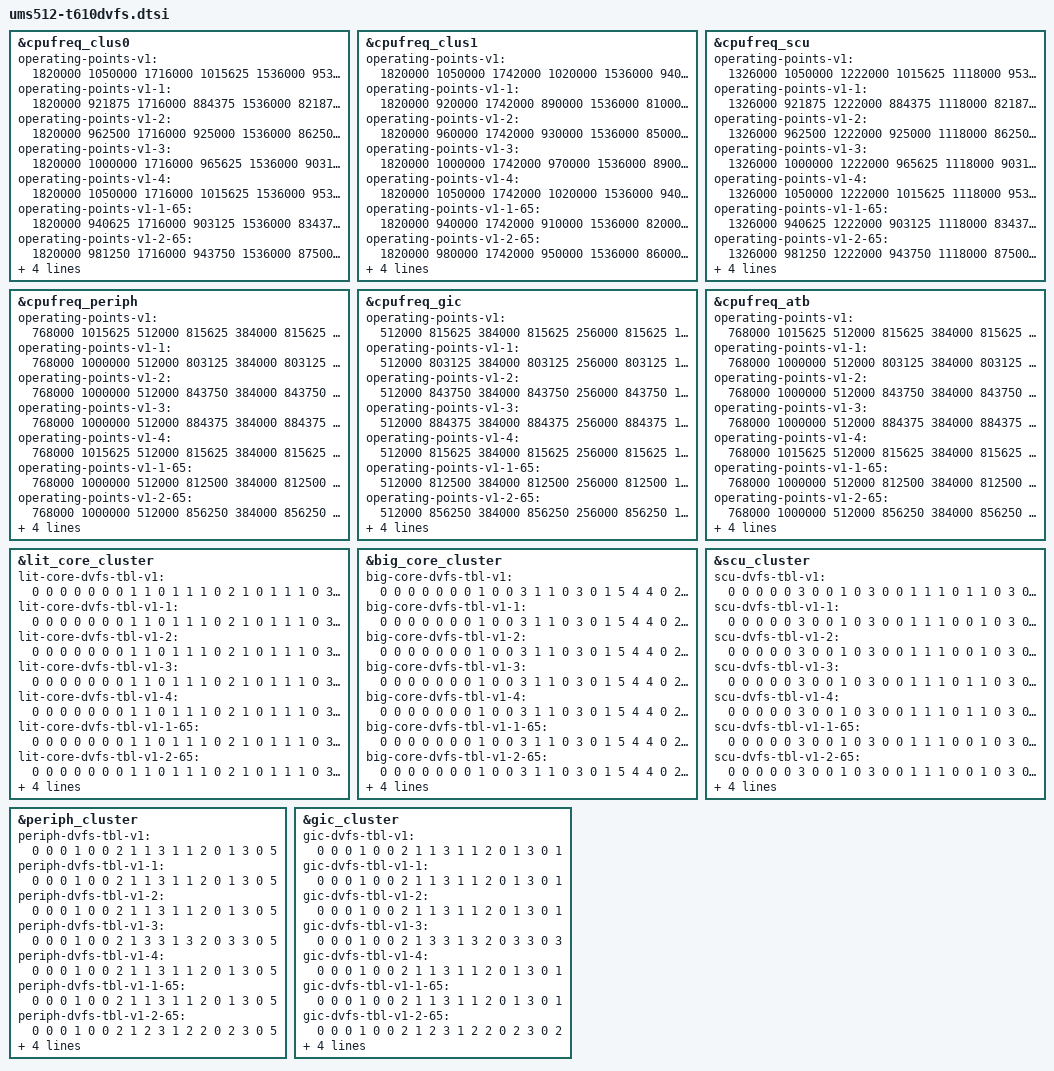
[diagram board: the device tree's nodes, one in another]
// SPDX-License-Identifier: (GPL-2.0+ OR MIT)
/*
 * Unisoc Sharkl5Pro platform T610 SOC DVFS DTS file
 *
 * Copyright (C) 2019, Unisoc Communications Inc.
 */

#include "sharkl5Pro.dtsi"
#include "ums512.dtsi"

&cpufreq_clus0 {
	/* operating-points-v1-0-0
	 * v0/v1-soc_ver 0-binning 0-temp
	 * v0-T618 v1-T610
	 */
	operating-points-v1 = <
		/* kHZ   uV */
		1820000 1050000
		1716000 1015625
		1536000 953125
		1482000 934375
		1228800 846875
		1144000 815625
		962000  753125
		768000  753125
		614400  753125
	>;

	operating-points-v1-1 = <
		/* kHZ   uV */
		1820000 921875
		1716000 884375
		1536000 821875
		1482000 803125
		1228800 750000
		1144000 750000
		962000  750000
		768000  750000
		614400  750000
	>;

	operating-points-v1-2 = <
		/* kHZ   uV */
		1820000 962500
		1716000 925000
		1536000 862500
		1482000 843750
		1228800 756250
		1144000 756250
		962000  756250
		768000  756250
		614400  756250
	>;

	operating-points-v1-3 = <
		/* kHZ   uV */
		1820000 1000000
		1716000 965625
		1536000 903125
		1482000 884375
		1228800 796875
		1144000 765625
		962000  750000
		768000  750000
		614400  750000
	>;

	operating-points-v1-4 = <
		/* kHZ   uV */
		1820000 1050000
		1716000 1015625
		1536000 953125
		1482000 934375
		1228800 846875
		1144000 815625
		962000  753125
		768000  753125
		614400  753125
	>;

	operating-points-v1-1-65 = <
		/* kHZ   uV */
		1820000 940625
		1716000 903125
		1536000 834375
		1482000 812500
		1228800 750000
		1144000 750000
		962000  750000
		768000  750000
		614400  750000
	>;

	operating-points-v1-2-65 = <
		/* kHZ   uV */
		1820000 981250
		1716000 943750
		1536000 875000
		1482000 856250
		1228800 759375
		1144000 750000
		962000  750000
		768000  750000
		614400  750000
	>;

	operating-points-v1-3-65 = <
		/* kHZ   uV */
		1820000 1021875
		1716000 984375
		1536000 915625
		1482000 896875
		1228800 803125
		1144000 771875
		962000  750000
		768000  750000
		614400  750000
	>;

	operating-points-v1-4-65 = <
		/* kHZ   uV */
		1716000 1034375
		1536000 965625
		1482000 946875
		1228800 853125
		1144000 821875
		962000  756250
		768000  756250
		614400  756250
	>;
};

&cpufreq_clus1 {
	operating-points-v1 = <
		/* kHZ   uV */
		1820000  1050000
		1742000  1020000
		1536000	 940000
		1482000	 920000
		1228800	 820000
	>;

	operating-points-v1-1 = <
		/* kHZ   uV */
		1820000  920000
		1742000  890000
		1536000	 810000
		1482000	 790000
		1228800	 750000
	>;

	operating-points-v1-2 = <
		/* kHZ   uV */
		1820000  960000
		1742000  930000
		1536000	 850000
		1482000	 830000
		1228800	 750000
	>;

	operating-points-v1-3 = <
		/* kHZ   uV */
		1820000  1000000
		1742000  970000
		1536000	 890000
		1482000	 870000
		1228800	 770000
	>;

	operating-points-v1-4 = <
		/* kHZ   uV */
		1820000  1050000
		1742000  1020000
		1536000	 940000
		1482000	 920000
		1228800	 820000
	>;

	operating-points-v1-1-65 = <
		/* kHZ   uV */
		1820000  940000
		1742000  910000
		1536000	 820000
		1482000	 800000
		1228800	 750000
	>;

	operating-points-v1-2-65 = <
		/* kHZ   uV */
		1820000  980000
		1742000  950000
		1536000	 860000
		1482000	 840000
		1228800	 750000
	>;

	operating-points-v1-3-65 = <
		/* kHZ   uV */
		1820000  1020000
		1742000  990000
		1536000	 900000
		1482000	 880000
		1228800	 770000
	>;

	operating-points-v1-4-65 = <
		/* kHZ   uV */
		1742000  1040000
		1536000	 960000
		1482000	 930000
		1228800	 830000
	>;
};

&cpufreq_scu {
	operating-points-v1 = <
		/* kHz   uV */
		1326000 1050000
		1222000 1015625
		1118000 953125
		1014000 934375
		962000  846875
		768000  815625
		650000  753125
		546000  753125
	>;

	operating-points-v1-1 = <
		/* kHz   uV */
		1326000 921875
		1222000 884375
		1118000 821875
		1014000 803125
		962000  750000
		768000  750000
		650000  750000
		546000  750000
	>;

	operating-points-v1-2 = <
		/* kHz   uV */
		1326000 962500
		1222000 925000
		1118000 862500
		1014000 843750
		962000  756250
		768000  756250
		650000  756250
		546000  756250
	>;

	operating-points-v1-3 = <
		/* kHz   uV */
		1326000 1000000
		1222000 965625
		1118000 903125
		1014000 884375
		962000  796875
		768000  765625
		650000  750000
		546000  750000
	>;

	operating-points-v1-4 = <
		/* kHz   uV */
		1326000 1050000
		1222000 1015625
		1118000 953125
		1014000 934375
		962000  846875
		768000  815625
		650000  753125
		546000  753125
	>;

	operating-points-v1-1-65 = <
		/* kHz   uV */
		1326000 940625
		1222000 903125
		1118000 834375
		1014000 812500
		962000  750000
		768000  750000
		650000  750000
		546000  750000
	>;

	operating-points-v1-2-65 = <
		/* kHz   uV */
		1326000 981250
		1222000 943750
		1118000 875000
		1014000 856250
		962000  759375
		768000  750000
		650000  750000
		546000  750000
	>;

	operating-points-v1-3-65 = <
		/* kHz   uV */
		1326000 1021875
		1222000 984375
		1118000 915625
		1014000 896875
		962000  803125
		768000  771875
		650000  750000
		546000  750000
	>;

	operating-points-v1-4-65 = <
		/* kHz   uV */
		1222000 1034375
		1118000 965625
		1014000 946875
		962000  853125
		768000  821875
		650000  756250
		546000  756250
	>;
};

&cpufreq_periph {
	operating-points-v1 = <
		/* kHZ  uV */
		768000 1015625
		512000 815625
		384000 815625
		256000 815625
		153600 753125
	>;

	operating-points-v1-1 = <
		/* kHZ  uV */
		768000 1000000
		512000 803125
		384000 803125
		256000 803125
		153600 750000
	>;

	operating-points-v1-2 = <
		/* kHZ  uV */
		768000 1000000
		512000 843750
		384000 843750
		256000 843750
		153600 756250
	>;

	operating-points-v1-3 = <
		/* kHZ  uV */
		768000 1000000
		512000 884375
		384000 884375
		256000 884375
		153600 750000
	>;

	operating-points-v1-4 = <
		/* kHZ  uV */
		768000 1015625
		512000 815625
		384000 815625
		256000 815625
		153600 753125
	>;

	operating-points-v1-1-65 = <
		/* kHZ  uV */
		768000 1000000
		512000 812500
		384000 812500
		256000 812500
		153600 750000
	>;

	operating-points-v1-2-65 = <
		/* kHZ  uV */
		768000 1000000
		512000 856250
		384000 856250
		256000 856250
		153600 750000
	>;

	operating-points-v1-3-65 = <
		/* kHZ  uV */
		768000 1021875
		512000 803125
		384000 803125
		256000 803125
		153600 750000
	>;

	operating-points-v1-4-65 = <
		/* kHZ  uV */
		768000 1034375
		512000 821875
		384000 821875
		256000 821875
		153600 756250
	>;
};

&cpufreq_gic {
	operating-points-v1 = <
		/* kHZ  uV */
		512000 815625
		384000 815625
		256000 815625
		192000 815625
		153600 753125
	>;

	operating-points-v1-1 = <
		/* kHZ  uV */
		512000 803125
		384000 803125
		256000 803125
		192000 803125
		153600 750000
	>;

	operating-points-v1-2 = <
		/* kHZ  uV */
		512000 843750
		384000 843750
		256000 843750
		192000 843750
		153600 756250
	>;

	operating-points-v1-3 = <
		/* kHZ  uV */
		512000 884375
		384000 884375
		256000 884375
		192000 884375
		153600 750000
	>;

	operating-points-v1-4 = <
		/* kHZ  uV */
		512000 815625
		384000 815625
		256000 815625
		192000 815625
		153600 753125
	>;

	operating-points-v1-1-65 = <
		/* kHZ  uV */
		512000 812500
		384000 812500
		256000 812500
		192000 812500
		153600 750000
	>;

	operating-points-v1-2-65 = <
		/* kHZ  uV */
		512000 856250
		384000 856250
		256000 856250
		192000 856250
		153600 750000
	>;

	operating-points-v1-3-65 = <
		/* kHZ  uV */
		512000 803125
		384000 803125
		256000 803125
		192000 803125
		153600 750000
	>;

	operating-points-v1-4-65 = <
		/* kHZ  uV */
		512000 821875
		384000 821875
		256000 821875
		192000 821875
		153600 756250
	>;
};

&cpufreq_atb {
	operating-points-v1 = <
		/* kHZ  uV */
		768000 1015625
		512000 815625
		384000 815625
		256000 753125
		153600 753125
	>;

	operating-points-v1-1 = <
		/* kHZ  uV */
		768000 1000000
		512000 803125
		384000 803125
		256000 750000
		153600 750000
	>;

	operating-points-v1-2 = <
		/* kHZ  uV */
		768000 1000000
		512000 843750
		384000 843750
		256000 756250
		153600 756250
	>;

	operating-points-v1-3 = <
		/* kHZ  uV */
		768000 1000000
		512000 884375
		384000 884375
		256000 750000
		153600 750000
	>;

	operating-points-v1-4 = <
		/* kHZ  uV */
		768000 1015625
		512000 815625
		384000 815625
		256000 753125
		153600 753125
	>;

	operating-points-v1-1-65 = <
		/* kHZ  uV */
		768000 1000000
		512000 812500
		384000 812500
		256000 750000
		153600 750000
	>;

	operating-points-v1-2-65 = <
		/* kHZ  uV */
		768000 1000000
		512000 856250
		384000 856250
		256000 750000
		153600 750000
	>;

	operating-points-v1-3-65 = <
		/* kHZ  uV */
		768000 1021875
		512000 803125
		384000 803125
		256000 750000
		153600 750000
	>;

	operating-points-v1-4-65 = <
		/* kHZ  uV */
		768000 1034375
		512000 821875
		384000 821875
		256000 756250
		153600 756250
	>;
};

&lit_core_cluster{
	/* lit-core-dvfs-tbl-v1-0-0
	 * v0/v1-soc_ver v0-T618 v1-T610 0-binning 0-temp
	 * sel, div, vol, vote_scu, vote_peri, vote_gic, mpllx
	 */
	lit-core-dvfs-tbl-v1 = <
		0 0 0 0 0 0 0
		1 1 0 1 1 1 0
		2 1 0 1 1 1 0
		3 0 0 2 1 1 0
		3 0 1 3 1 1 1
		1 0 2 4 1 1 0
		3 0 3 5 4 4 2
		2 0 4 6 4 4 0
		3 0 5 7 4 5 3
		3 0 6 8 4 5 4
		3 0 6 8 4 5 4
	>;

	lit-core-dvfs-tbl-v1-1 = <
		0 0 0 0 0 0 0
		1 1 0 1 1 1 0
		2 1 0 1 1 1 0
		3 0 0 2 1 1 0
		3 0 0 3 1 1 1
		1 0 0 4 1 1 0
		3 0 1 5 4 4 2
		2 0 2 6 4 4 0
		3 0 3 7 4 5 3
		3 0 4 8 4 5 4
		3 0 4 8 4 5 4
	>;

	lit-core-dvfs-tbl-v1-2 = <
		0 0 0 0 0 0 0
		1 1 0 1 1 1 0
		2 1 0 1 1 1 0
		3 0 0 2 1 1 0
		3 0 0 3 1 1 1
		1 0 0 4 1 1 0
		3 0 1 5 4 4 2
		2 0 2 6 4 4 0
		3 0 3 7 4 5 3
		3 0 4 8 4 5 4
		3 0 4 8 4 5 4
	>;

	lit-core-dvfs-tbl-v1-3 = <
		0 0 0 0 0 0 0
		1 1 0 1 1 1 0
		2 1 0 1 1 1 0
		3 0 0 2 1 1 0
		3 0 1 3 1 1 1
		1 0 2 4 1 1 0
		3 0 3 5 4 4 2
		2 0 4 6 4 4 0
		3 0 5 7 4 5 3
		3 0 6 8 4 5 4
		3 0 6 8 4 5 4
	>;

	lit-core-dvfs-tbl-v1-4 = <
		0 0 0 0 0 0 0
		1 1 0 1 1 1 0
		2 1 0 1 1 1 0
		3 0 0 2 1 1 0
		3 0 1 3 1 1 1
		1 0 2 4 1 1 0
		3 0 3 5 4 4 2
		2 0 4 6 4 4 0
		3 0 5 7 4 5 3
		3 0 6 8 4 5 4
		3 0 6 8 4 5 4
	>;

	lit-core-dvfs-tbl-v1-1-65 = <
		0 0 0 0 0 0 0
		1 1 0 1 1 1 0
		2 1 0 1 1 1 0
		3 0 0 2 1 1 0
		3 0 0 3 1 1 1
		1 0 0 4 1 1 0
		3 0 1 5 4 4 2
		2 0 2 6 4 4 0
		3 0 3 7 4 5 3
		3 0 4 8 4 5 4
		3 0 4 8 4 5 4
	>;

	lit-core-dvfs-tbl-v1-2-65 = <
		0 0 0 0 0 0 0
		1 1 0 1 1 1 0
		2 1 0 1 1 1 0
		3 0 0 2 1 1 0
		3 0 0 3 1 1 1
		1 0 1 4 1 1 0
		3 0 2 5 4 4 2
		2 0 3 6 4 4 0
		3 0 4 7 4 5 3
		3 0 5 8 4 5 4
		3 0 5 8 4 5 4
	>;

	lit-core-dvfs-tbl-v1-3-65 = <
		0 0 0 0 0 0 0
		1 1 0 1 1 1 0
		2 1 0 1 1 1 0
		3 0 0 2 1 1 0
		3 0 1 3 1 1 1
		1 0 2 4 1 1 0
		3 0 3 5 4 4 2
		2 0 4 6 4 4 0
		3 0 5 7 4 5 3
		3 0 6 8 4 5 4
		3 0 6 8 4 5 4
	>;

	lit-core-dvfs-tbl-v1-4-65 = <
		0 0 0 0 0 0 0
		1 1 0 1 1 1 0
		2 1 0 1 1 1 0
		3 0 0 2 1 1 0
		3 0 1 3 1 1 1
		1 0 2 4 1 1 0
		3 0 3 5 4 4 2
		2 0 4 6 4 4 0
		3 0 5 7 4 5 3
		3 0 5 7 4 5 3
		3 0 5 7 4 5 3
	>;
};

&big_core_cluster {
	/* sel, div, vol, vote_scu, vote_peri, vote_gic, mpllx */
	big-core-dvfs-tbl-v1 = <
		0 0 0 0 0 0 0
		1 0 0 3 1 1 0
		3 0 1 5 4 4 0
		2 0 2 6 4 4 0
		3 0 3 7 4 5 1
		3 0 4 8 4 5 2
		3 0 4 8 4 5 2
	>;

	big-core-dvfs-tbl-v1-1 = <
		0 0 0 0 0 0 0
		1 0 0 3 1 1 0
		3 0 1 5 4 4 0
		2 0 2 6 4 4 0
		3 0 3 7 4 5 1
		3 0 4 8 4 5 2
		3 0 4 8 4 5 2
	>;

	big-core-dvfs-tbl-v1-2 = <
		0 0 0 0 0 0 0
		1 0 0 3 1 1 0
		3 0 1 5 4 4 0
		2 0 2 6 4 4 0
		3 0 3 7 4 5 1
		3 0 4 8 4 5 2
		3 0 4 8 4 5 2
	>;

	big-core-dvfs-tbl-v1-3 = <
		0 0 0 0 0 0 0
		1 0 0 3 1 1 0
		3 0 1 5 4 4 0
		2 0 2 6 4 4 0
		3 0 3 7 4 5 1
		3 0 4 8 4 5 2
		3 0 4 8 4 5 2
	>;

	big-core-dvfs-tbl-v1-4 = <
		0 0 0 0 0 0 0
		1 0 0 3 1 1 0
		3 0 1 5 4 4 0
		2 0 2 6 4 4 0
		3 0 3 7 4 5 1
		3 0 4 8 4 5 2
		3 0 4 8 4 5 2
	>;

	big-core-dvfs-tbl-v1-1-65 = <
		0 0 0 0 0 0 0
		1 0 0 3 1 1 0
		3 0 1 5 4 4 0
		2 0 2 6 4 4 0
		3 0 3 7 4 5 1
		3 0 4 8 4 5 2
		3 0 4 8 4 5 2
	>;

	big-core-dvfs-tbl-v1-2-65 = <
		0 0 0 0 0 0 0
		1 0 0 3 1 1 0
		3 0 1 5 4 4 0
		2 0 2 6 4 4 0
		3 0 3 7 4 5 1
		3 0 4 8 4 5 2
		3 0 4 8 4 5 2
	>;

	big-core-dvfs-tbl-v1-3-65 = <
		0 0 0 0 0 0 0
		1 0 0 3 1 1 0
		3 0 1 5 4 4 0
		2 0 2 6 4 4 0
		3 0 3 7 4 5 1
		3 0 4 8 4 5 2
		3 0 4 8 4 5 2
	>;

	big-core-dvfs-tbl-v1-4-65 = <
		0 0 0 0 0 0 0
		1 0 0 3 1 1 0
		3 0 1 5 4 4 0
		2 0 2 6 4 4 0
		3 0 3 7 4 5 1
		3 0 3 7 4 5 1
		3 0 3 7 4 5 1
	>;
};

&scu_cluster {
	/* sel div vol ace_div mpllx */
	scu-dvfs-tbl-v1 = <
		0 0 0 0 0
		3 0 0 1 0
		3 0 0 1 1
		1 0 1 1 0
		3 0 2 1 2
		3 0 3 1 3
		3 0 4 1 4
		3 0 5 1 5
		3 0 6 1 6
		3 0 6 1 6
	>;

	scu-dvfs-tbl-v1-1 = <
		0 0 0 0 0
		3 0 0 1 0
		3 0 0 1 1
		1 0 0 1 0
		3 0 0 1 2
		3 0 1 1 3
		3 0 2 1 4
		3 0 3 1 5
		3 0 4 1 6
		3 0 4 1 6
	>;

	scu-dvfs-tbl-v1-2 = <
		0 0 0 0 0
		3 0 0 1 0
		3 0 0 1 1
		1 0 0 1 0
		3 0 0 1 2
		3 0 1 1 3
		3 0 2 1 4
		3 0 3 1 5
		3 0 4 1 6
		3 0 4 1 6
	>;

	scu-dvfs-tbl-v1-3 = <
		0 0 0 0 0
		3 0 0 1 0
		3 0 0 1 1
		1 0 1 1 0
		3 0 2 1 2
		3 0 3 1 3
		3 0 4 1 4
		3 0 5 1 5
		3 0 6 1 6
		3 0 6 1 6
	>;

	scu-dvfs-tbl-v1-4 = <
		0 0 0 0 0
		3 0 0 1 0
		3 0 0 1 1
		1 0 1 1 0
		3 0 2 1 2
		3 0 3 1 3
		3 0 4 1 4
		3 0 5 1 5
		3 0 6 1 6
		3 0 6 1 6
	>;

	scu-dvfs-tbl-v1-1-65 = <
		0 0 0 0 0
		3 0 0 1 0
		3 0 0 1 1
		1 0 0 1 0
		3 0 0 1 2
		3 0 1 1 3
		3 0 2 1 4
		3 0 3 1 5
		3 0 4 1 6
		3 0 4 1 6
	>;

	scu-dvfs-tbl-v1-2-65 = <
		0 0 0 0 0
		3 0 0 1 0
		3 0 0 1 1
		1 0 0 1 0
		3 0 1 1 2
		3 0 2 1 3
		3 0 3 1 4
		3 0 4 1 5
		3 0 5 1 6
		3 0 5 1 6
	>;

	scu-dvfs-tbl-v1-3-65 = <
		0 0 0 0 0
		3 0 0 1 0
		3 0 0 1 1
		1 0 1 1 0
		3 0 2 1 2
		3 0 3 1 3
		3 0 4 1 4
		3 0 5 1 5
		3 0 6 1 6
		3 0 6 1 6
	>;

	scu-dvfs-tbl-v1-4-65 = <
		0 0 0 0 0
		3 0 0 1 0
		3 0 0 1 1
		1 0 1 1 0
		3 0 2 1 2
		3 0 3 1 3
		3 0 4 1 4
		3 0 5 1 5
		3 0 5 1 5
		3 0 5 1 5
	>;
};

&periph_cluster{
	/* sel div vol */
	periph-dvfs-tbl-v1 = <
		0 0 0
		1 0 0
		2 1 1
		3 1 1
		2 0 1
		3 0 5
	>;

	periph-dvfs-tbl-v1-1 = <
		0 0 0
		1 0 0
		2 1 1
		3 1 1
		2 0 1
		3 0 5
	>;

	periph-dvfs-tbl-v1-2 = <
		0 0 0
		1 0 0
		2 1 1
		3 1 1
		2 0 1
		3 0 5
	>;

	periph-dvfs-tbl-v1-3 = <
		0 0 0
		1 0 0
		2 1 3
		3 1 3
		2 0 3
		3 0 5
	>;

	periph-dvfs-tbl-v1-4 = <
		0 0 0
		1 0 0
		2 1 1
		3 1 1
		2 0 1
		3 0 5
	>;

	periph-dvfs-tbl-v1-1-65 = <
		0 0 0
		1 0 0
		2 1 1
		3 1 1
		2 0 1
		3 0 5
	>;

	periph-dvfs-tbl-v1-2-65 = <
		0 0 0
		1 0 0
		2 1 2
		3 1 2
		2 0 2
		3 0 5
	>;

	periph-dvfs-tbl-v1-3-65 = <
		0 0 0
		1 0 0
		2 1 2
		3 1 2
		2 0 2
		3 0 5
	>;

	periph-dvfs-tbl-v1-4-65 = <
		0 0 0
		1 0 0
		2 1 1
		3 1 1
		2 0 1
		3 0 5
	>;
};

&gic_cluster {
	/*sel div vol*/
	gic-dvfs-tbl-v1 = <
		0 0 0
		1 0 0
		2 1 1
		3 1 1
		2 0 1
		3 0 1
	>;

	gic-dvfs-tbl-v1-1 = <
		0 0 0
		1 0 0
		2 1 1
		3 1 1
		2 0 1
		3 0 1
	>;

	gic-dvfs-tbl-v1-2 = <
		0 0 0
		1 0 0
		2 1 1
		3 1 1
		2 0 1
		3 0 1
	>;

	gic-dvfs-tbl-v1-3 = <
		0 0 0
		1 0 0
		2 1 3
		3 1 3
		2 0 3
		3 0 3
	>;

	gic-dvfs-tbl-v1-4 = <
		0 0 0
		1 0 0
		2 1 1
		3 1 1
		2 0 1
		3 0 1
	>;

	gic-dvfs-tbl-v1-1-65 = <
		0 0 0
		1 0 0
		2 1 1
		3 1 1
		2 0 1
		3 0 1
	>;

	gic-dvfs-tbl-v1-2-65 = <
		0 0 0
		1 0 0
		2 1 2
		3 1 2
		2 0 2
		3 0 2
	>;

	gic-dvfs-tbl-v1-3-65 = <
		0 0 0
		1 0 0
		2 1 2
		3 1 2
		2 0 2
		3 0 2
	>;

	gic-dvfs-tbl-v1-4-65 = <
		0 0 0
		1 0 0
		2 1 1
		3 1 1
		2 0 1
		3 0 1
	>;
};
